AUTOSAR XML (schema 00049)
package /Application/DltConfig
  dlt log channel to process mapping DltLogChannelToProcessMapping_KATECH_TO_KATECH: dlt-log-channel=KATECH, process=KATECH
package /Application/Executable
  executable KATECH: category=APPLICATION_LEVEL, logging-behavior=DOES-NOT-USE-LOGGING, reporting-behavior=REPORTS-EXECUTION-STATE, version=1.0.0
    root sw component prototype AA: application-type=KATECH
package /Application/Manifest
  service instance to port prototype mapping KATECH_AA_KATEHCH_PPort: port-prototype=AA.PPortRearCurtain, service-instance=EEVP_KATECH_Provider_SoaRcurtain
  service instance to port prototype mapping KATECH_AA_KATEHCH_RPort: port-prototype=AA.RPortRoa, service-instance=EEVP_KATECH_Consumer_SoaRoa
package /Application/Process
  process KATECH: executable=KATECH, state-dependent-startup-config{execution-dependency=CM.Running, function-group-state=MachineFG.Startup, resource-group=DefaultResourceGroup, startup-config=KATECH}
    process state machine KATECH: type=ProcessState
package /Application/StartupConfig
  startup config set EEVP_KATECH_StartupConfig
    startup config KATECH: scheduling-policy=SCHED_OTHER, scheduling-priority=0
package /Application/SwComponent
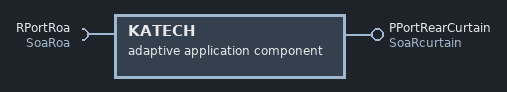
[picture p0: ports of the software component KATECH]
  adaptive application sw component type KATECH
    provide port PPortRearCurtain: provided-interface=SoaRcurtain
    require port RPortRoa: required-interface=SoaRoa
